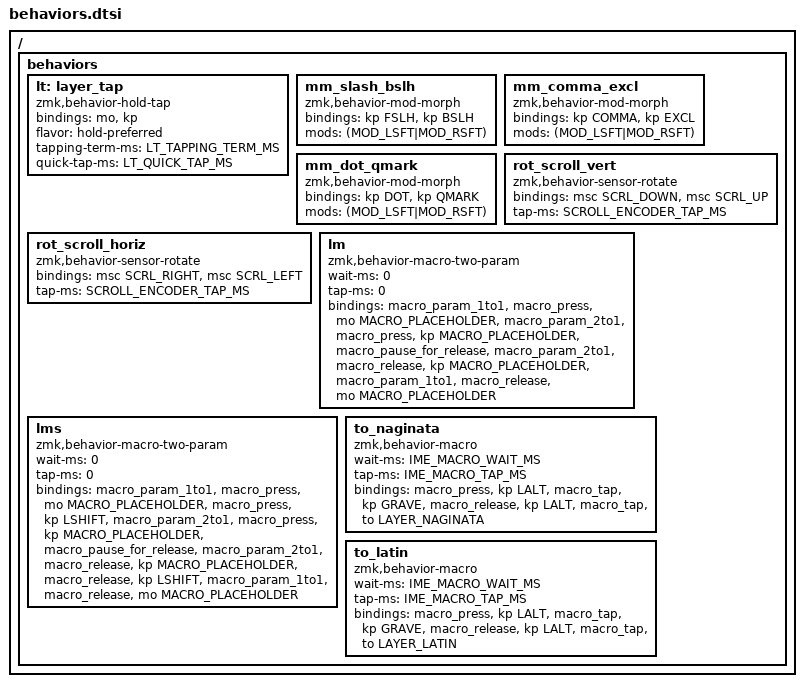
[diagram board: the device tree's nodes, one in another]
/*
 * Copyright (c) 2020 The ZMK Contributors
 *
 * SPDX-License-Identifier: MIT
 */

#pragma once

#include "layers.h"
#include "settings.h"

/ {
    behaviors {
        lt: layer_tap {
            compatible = "zmk,behavior-hold-tap";
            #binding-cells = <2>;
            bindings = <&mo>, <&kp>;

            flavor = "hold-preferred";
            tapping-term-ms = <LT_TAPPING_TERM_MS>;
            quick-tap-ms = <LT_QUICK_TAP_MS>;
        };

        mm_slash_bslh: mm_slash_bslh {
            compatible = "zmk,behavior-mod-morph";
            #binding-cells = <0>;
            bindings = <&kp FSLH>, <&kp BSLH>;
            mods = <(MOD_LSFT|MOD_RSFT)>;
        };

        mm_comma_excl: mm_comma_excl {
            compatible = "zmk,behavior-mod-morph";
            #binding-cells = <0>;
            bindings = <&kp COMMA>, <&kp EXCL>;
            mods = <(MOD_LSFT|MOD_RSFT)>;
        };

        mm_dot_qmark: mm_dot_qmark {
            compatible = "zmk,behavior-mod-morph";
            #binding-cells = <0>;
            bindings = <&kp DOT>, <&kp QMARK>;
            mods = <(MOD_LSFT|MOD_RSFT)>;
        };

#define SHIFT_IMMUNE_MM(name, keycode) \
        name: name { \
            compatible = "zmk,behavior-mod-morph"; \
            #binding-cells = <0>; \
            bindings = <keycode>, <keycode>; \
            mods = <(MOD_LSFT|MOD_RSFT)>; \
        };

        /*
         * Shift-Immune Mod-Morphs (custom/layout.md 凡例仕様)
         * 記号面において Shift 押下時でも同一文字出力を維持するためのビヘイビア
         */
        SHIFT_IMMUNE_MM(mm_n0, &kp N0)
        SHIFT_IMMUNE_MM(mm_n1, &kp N1)
        SHIFT_IMMUNE_MM(mm_n2, &kp N2)
        SHIFT_IMMUNE_MM(mm_n3, &kp N3)
        SHIFT_IMMUNE_MM(mm_n4, &kp N4)
        SHIFT_IMMUNE_MM(mm_n5, &kp N5)
        SHIFT_IMMUNE_MM(mm_n6, &kp N6)
        SHIFT_IMMUNE_MM(mm_n7, &kp N7)
        SHIFT_IMMUNE_MM(mm_n8, &kp N8)
        SHIFT_IMMUNE_MM(mm_n9, &kp N9)
        SHIFT_IMMUNE_MM(mm_lbkt, &kp LBKT)
        SHIFT_IMMUNE_MM(mm_rbkt, &kp RBKT)
        SHIFT_IMMUNE_MM(mm_semi, &kp SEMI)
        SHIFT_IMMUNE_MM(mm_equal, &kp EQUAL)
        SHIFT_IMMUNE_MM(mm_fslh, &kp FSLH)
#undef SHIFT_IMMUNE_MM

        rot_scroll_vert: rot_scroll_vert {
            compatible = "zmk,behavior-sensor-rotate";
            #sensor-binding-cells = <0>;
            bindings = <&msc SCRL_DOWN>, <&msc SCRL_UP>;
            tap-ms = <SCROLL_ENCODER_TAP_MS>;
        };

        rot_scroll_horiz: rot_scroll_horiz {
            compatible = "zmk,behavior-sensor-rotate";
            #sensor-binding-cells = <0>;
            bindings = <&msc SCRL_RIGHT>, <&msc SCRL_LEFT>;
            tap-ms = <SCROLL_ENCODER_TAP_MS>;
        };

        lm: lm {
            compatible = "zmk,behavior-macro-two-param";
            wait-ms = <0>;
            tap-ms = <0>;
            #binding-cells = <2>;
            bindings
                = <&macro_param_1to1 &macro_press &mo MACRO_PLACEHOLDER>
                , <&macro_param_2to1 &macro_press &kp MACRO_PLACEHOLDER>
                , <&macro_pause_for_release>
                , <&macro_param_2to1 &macro_release &kp MACRO_PLACEHOLDER>
                , <&macro_param_1to1 &macro_release &mo MACRO_PLACEHOLDER>;
        };

        lms: lms {
            compatible = "zmk,behavior-macro-two-param";
            wait-ms = <0>;
            tap-ms = <0>;
            #binding-cells = <2>;
            bindings
                = <&macro_param_1to1 &macro_press &mo MACRO_PLACEHOLDER>
                , <&macro_press &kp LSHIFT>
                , <&macro_param_2to1 &macro_press &kp MACRO_PLACEHOLDER>
                , <&macro_pause_for_release>
                , <&macro_param_2to1 &macro_release &kp MACRO_PLACEHOLDER>
                , <&macro_release &kp LSHIFT>
                , <&macro_param_1to1 &macro_release &mo MACRO_PLACEHOLDER>;
        };

        to_naginata: to_naginata {
            compatible = "zmk,behavior-macro";
            #binding-cells = <0>;
            wait-ms = <IME_MACRO_WAIT_MS>;
            tap-ms = <IME_MACRO_TAP_MS>;
            bindings = <&macro_press &kp LALT>, <&macro_tap &kp GRAVE>, <&macro_release &kp LALT>, <&macro_tap &to LAYER_NAGINATA>;
        };

        to_latin: to_latin {
            compatible = "zmk,behavior-macro";
            #binding-cells = <0>;
            wait-ms = <IME_MACRO_WAIT_MS>;
            tap-ms = <IME_MACRO_TAP_MS>;
            bindings = <&macro_press &kp LALT>, <&macro_tap &kp GRAVE>, <&macro_release &kp LALT>, <&macro_tap &to LAYER_LATIN>;
        };
    };
};
